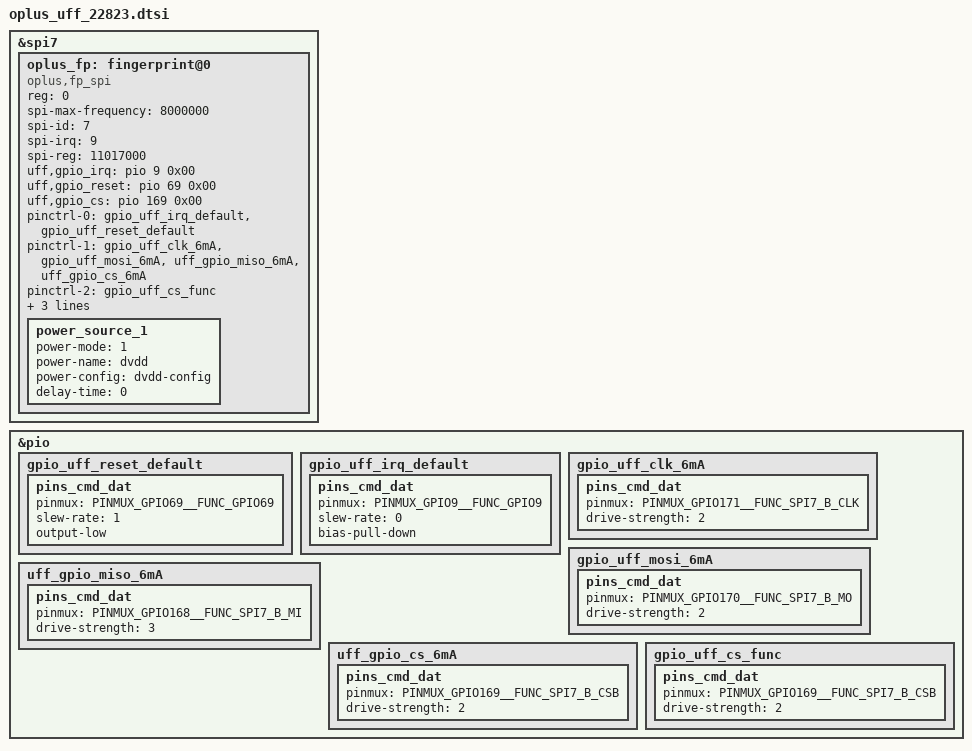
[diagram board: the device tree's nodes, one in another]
// SPDX-License-Identifier: GPL-2.0-only
/*
* Copyright (C) 2021-2025 Oplus. All rights reserved.
*/
#include <dt-bindings/iio/mt635x-auxadc.h>
#include <dt-bindings/pinctrl/mt6373-pinfunc.h>
#include <dt-bindings/pinctrl/mt65xx.h>

/* UFF dts config at 2021.12.22
 *
 * fp vendor:
 *   jiiov: 0301
 *   goodix:
 */

&spi7 {
#address-cells = <1>;
#size-cells = <0>;
status = "okay";

oplus_fp: fingerprint@0 {
    /* UFF especial */
    compatible = "oplus,fp_spi";

    reg = <0>;
    spi-max-frequency = <8000000>;
    spi-id = <7>;
    spi-irq = <9>;
    spi-reg = <11017000>;

    /* UFF gpio begin */
    /* UFF gpio irq */
    uff,gpio_irq = <&pio 9 0x00>;

    /* UFF gpio rst */
    uff,gpio_reset = <&pio 69 0x00>;

    /* UFF gpio cs */
    uff,gpio_cs = <&pio 169 0x00>;

    pinctrl-names = "default", "fp_spi_driver", "fp_cs_func";
    pinctrl-0 = <&gpio_uff_irq_default>, <&gpio_uff_reset_default>;
    pinctrl-1 = <&gpio_uff_clk_6mA>, <&gpio_uff_mosi_6mA>, <&uff_gpio_miso_6mA>, <&uff_gpio_cs_6mA>;
    pinctrl-2 = <&gpio_uff_cs_func>;

    dvdd-supply = <&mt6373_vfp>;
    dvdd-config = <3300000 3300000 150000>;
    power-num = <1>;
    status = "okay";
    power_source_1 {
        power-mode = <1>;
        power-name = "dvdd";
        power-config = "dvdd-config";
        delay-time = <0>;
    };
};
};

&pio{
    gpio_uff_reset_default: gpio_uff_reset_default {
        pins_cmd_dat {
            pinmux = <PINMUX_GPIO69__FUNC_GPIO69>;
            slew-rate = <1>;
            output-low;
        };
    };

    gpio_uff_irq_default: gpio_uff_irq_default {
        pins_cmd_dat {
            pinmux = <PINMUX_GPIO9__FUNC_GPIO9>;
            slew-rate = <0>;
            bias-pull-down;
        };
    };

    gpio_uff_clk_6mA: gpio_uff_clk_6mA {
        pins_cmd_dat {
            pinmux = <PINMUX_GPIO171__FUNC_SPI7_B_CLK>;
            drive-strength = <2>;
        };
    };

    gpio_uff_mosi_6mA: gpio_uff_mosi_6mA {
        pins_cmd_dat {
            pinmux = <PINMUX_GPIO170__FUNC_SPI7_B_MO>;
            drive-strength = <2>;
        };
    };

    uff_gpio_miso_6mA: uff_gpio_miso_6mA {
        pins_cmd_dat {
            pinmux = <PINMUX_GPIO168__FUNC_SPI7_B_MI>;
            drive-strength = <3>;
        };
    };

    uff_gpio_cs_6mA: uff_gpio_cs_6mA{
        pins_cmd_dat {
            pinmux = <PINMUX_GPIO169__FUNC_SPI7_B_CSB>;
            drive-strength = <2>;
        };
    };

    gpio_uff_cs_func: gpio_uff_cs_func {
        pins_cmd_dat {
            pinmux = <PINMUX_GPIO169__FUNC_SPI7_B_CSB>;
            drive-strength = <2>;
        };
    };
};
